# max32650 register map
Vendor: Maxim-Integrated; Series: ARMCM4; File version: 1.1
CPU: CM4 r2p1, little endian, MPU, FPU, 3 interrupt priority bits
Registers are 32-bit, read-write, reset 0x0 unless marked. A register's access mark holds for its fields unless they carry their own. Offsets are from the block's base; [hi:lo] are bit positions; {n}, {i} and the like mark numbered series.

## PTG — Pulse Train Generation
Base 0x4003C000
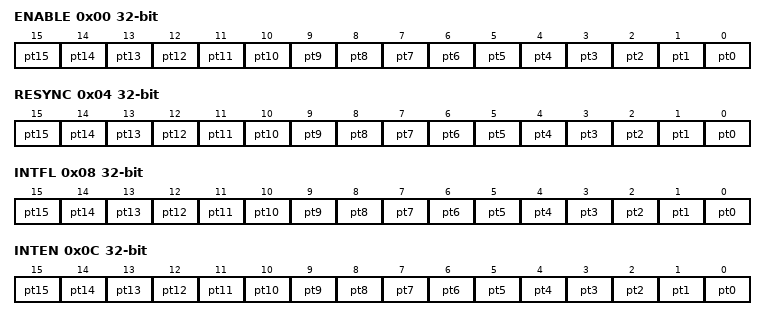
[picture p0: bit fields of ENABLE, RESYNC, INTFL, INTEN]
0x00 ENABLE — Global Enable/Disable Controls for All Pulse Trains
  [n] pt{n} (n=0..15) — Enable/Disable control for PT{n}
0x04 RESYNC — Global Resync (All Pulse Trains) Control
  [n] pt{n} (n=0..15) — Resync control for PT{n}
0x08 INTFL — Pulse Train Interrupt Flags
  [n] pt{n} (n=0..15) — Pulse Train {n} Stopped Interrupt Flag
0x0C INTEN — Pulse Train Interrupt Enable/Disable
  [n] pt{n} (n=0..15) — Pulse Train {n} Stopped Interrupt Enable/Disable
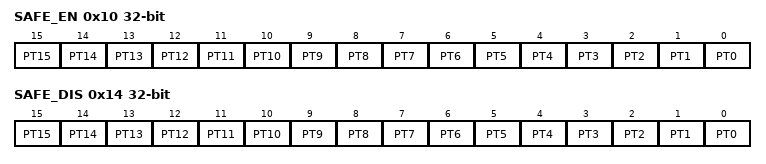
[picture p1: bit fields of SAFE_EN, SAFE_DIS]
0x10 SAFE_EN wo — Pulse Train Global Safe Enable.
  [n] PT{n} (n=0..15)
0x14 SAFE_DIS wo — Pulse Train Global Safe Disable.
  [n] PT{n} (n=0..15)

## RTC — Real Time Clock and Alarm.
Base 0x40006000
0x00 SEC reset not defined — RTC Second Counter. This register contains the 32-bit second counter.
  [31:0] SEC — RTC Seconds Counter.
0x04 SSEC reset not defined — RTC Sub-second Counter. This counter increments at 256Hz. RTC_SEC is incremented when this register rolls over from 0xFF to 0x00.
  [7:0] SSEC — RTC Sub-second Counter.
0x08 TODA reset not defined — Time-of-day Alarm.
  [19:0] TOD_ALARM
0x0C SSECA reset not defined — RTC sub-second alarm. This register contains the reload value for the sub-second alarm.
  [31:0] SSEC_ALARM — This register contains the reload value for the sub-second alarm.
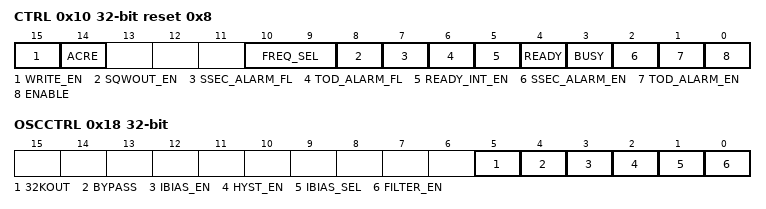
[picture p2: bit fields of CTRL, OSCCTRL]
0x10 CTRL reset 0x8 (reset mask 0xFFFFFF38) — RTC Control Register.
  [15] WRITE_EN — Write Enable. This register bit serves as a protection mechanism against unintentional writes to critical RTC bits.
    0=dis (Writes to RTC_CTRL.enable are ignored.); 1=en (Writes to RTC_CTRL.enable are allowed.)
  [14] ACRE — Asynchronous Counter Read Enable.
    0=sync (SEC and SSEC registers synchronized and should only be accessed while CTRL.rdy = 1.); 1=async (SEC and SSEC registers are asynchronous and will require software interaction to ensure data accuracy.)
  [10:9] FREQ_SEL — Frequency Output Selection. When SQE=1, these bits specify the output frequency on the SQW pin.
    0=freq1Hz (1 Hz (Compensated).); 1=freq512Hz (512 Hz (Compensated).); 2=freq4KHz (4 KHz.)
  [8] SQWOUT_EN — Square Wave Output Enable.
    0=dis (Disabled.); 1=en (Enabled.)
  [7] SSEC_ALARM_FL ro — Sub-second Alarm Interrupt Flag. This alarm is qualified as wake-up source to the processor.
    0=inactive (Not active); 1=Pending (Active)
  [6] TOD_ALARM_FL ro — Time-of-Day Alarm Interrupt Flag. This alarm is qualified as wake-up source to the processor.
    0=inactive (Not active); 1=Pending (Active)
  [5] READY_INT_EN — RTC Ready Interrupt Enable.
    0=dis (Disable.); 1=en (Enable.)
  [4] READY — RTC Ready. This bit is set to 1 by hardware when the RTC count registers update. It can be cleared to 0 by software at any time. It will also be cleared to 0 by hardware just prior to an update of the RTC count register.
    0=not_ready (Register has not updated.); 1=ready
  [3] BUSY ro — RTC Busy. This bit is set to 1 by hardware when changes to RTC registers required a synchronized version of the register to be in place. This bit is automatically cleared by hardware.
    0=idle; 1=busy
  [2] SSEC_ALARM_EN — Alarm Sub-second Interrupt Enable. Change to this bit is effective only after BUSY is cleared from 1 to 0.
    0=dis (Disable.); 1=en (Enable.)
  [1] TOD_ALARM_EN — Alarm Time-of-Day Interrupt Enable. Change to this bit is effective only after BUSY is cleared from 1 to 0.
    0=dis (Disable.); 1=en (Enable.)
  [0] ENABLE — Real Time Clock Enable. This bit enables the Real Time Clock. This bit can only be written when WE=1 and BUSY =0. Change to this bit is effective only after BUSY is cleared from 1 to 0.
    0=dis (Disable.); 1=en (Enable.)
0x18 OSCCTRL reset not defined — RTC Oscillator Control Register.
  [5] 32KOUT — RTC 32kHz Square Wave Output
  [4] BYPASS — RTC Crystal Bypass
  [3] IBIAS_EN — Enables higher 4x,2x current modes.
  [2] HYST_EN — Enables high current hysteresis buffer.
  [1] IBIAS_SEL — If IBIAS_EN is 1, selects 4x,2x mode.
  [0] FILTER_EN — Enables analog deglitch filter.
